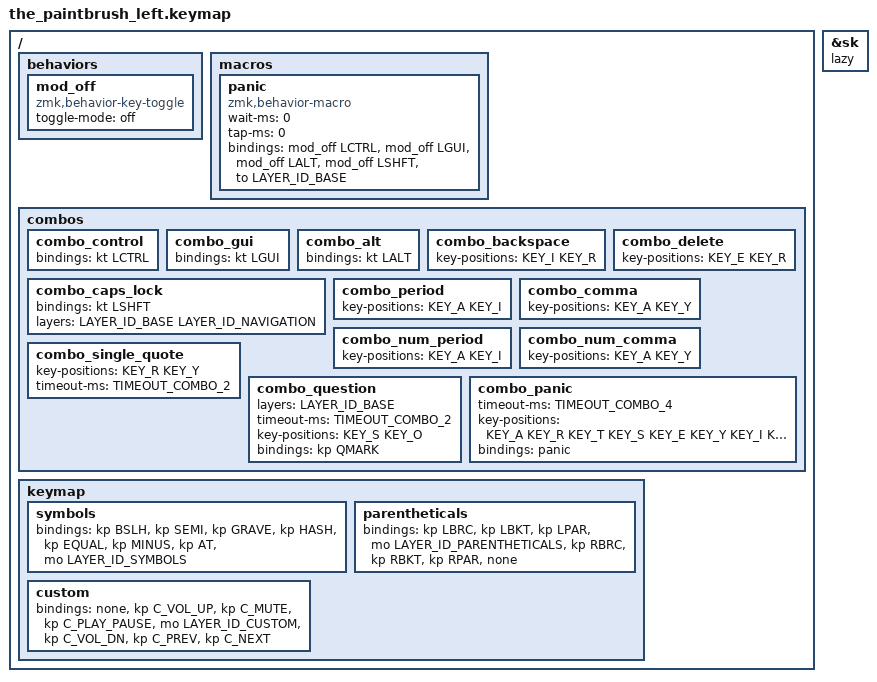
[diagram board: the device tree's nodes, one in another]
/*
 * Copyright (c) 2021 Mike "KemoNine" Crosson
 *
 * SPDX-License-Identifier: MIT
 */

#include <behaviors.dtsi>
#include <dt-bindings/zmk/keys.h>
#include <dt-bindings/zmk/bt.h>

// Left/Right
#define ARDUX_LEFT 1

// ARTS Row
#define KEY_A 3
#define KEY_R 2
#define KEY_T 1
#define KEY_S 0
// EYIO Row
#define KEY_E 7
#define KEY_Y 6
#define KEY_I 5
#define KEY_O 4

// Define Offsets
#define LEADING_NONES NONE(0,0,0)
#define MIDDLE_NONES NONE(0, 0, 0)
#define TRAILING_NONES NONE(0, 0, 0)

// Enable disconnecting for iPhone, iPad
#define ARDUX_BT_TOP &bt BT_DISC 4
#define ARDUX_BT_BOTTOM &bt BT_DISC 5

// Include main ardux.io keymap
#include "../../../ardux.dtsi"

// ARTSEY 0.9 beta overrides for this Paintbrush only. See docs/artsey-0.9.md.
// Defer one-shot Shift so it cannot interfere with the latched Shift state.
&sk { lazy; };
/ {
	behaviors {
		mod_off: mod_off {
			compatible = "zmk,behavior-key-toggle";
			#binding-cells = <1>;
			toggle-mode = "off";
		};
	};
	macros {
		panic: panic {
			compatible = "zmk,behavior-macro";
			#binding-cells = <0>;
			wait-ms = <0>;
			tap-ms = <0>;
			bindings = <&mod_off LCTRL &mod_off LGUI &mod_off LALT &mod_off LSHFT &to LAYER_ID_BASE>;
		};
	};
	combos {
		combo_control { bindings = <&kt LCTRL>; };
		combo_gui { bindings = <&kt LGUI>; };
		combo_alt { bindings = <&kt LALT>; };
		combo_backspace { key-positions = <KEY_I KEY_R>; };
		combo_delete { key-positions = <KEY_E KEY_R>; };
		/delete-node/ combo_shift_lock;
		combo_caps_lock { bindings = <&kt LSHFT>; layers = <LAYER_ID_BASE LAYER_ID_NAVIGATION>; };
		combo_period { key-positions = <KEY_A KEY_I>; };
		combo_comma { key-positions = <KEY_A KEY_Y>; };
		combo_num_period { key-positions = <KEY_A KEY_I>; };
		combo_num_comma { key-positions = <KEY_A KEY_Y>; };
		combo_single_quote { key-positions = <KEY_R KEY_Y>; timeout-ms = <TIMEOUT_COMBO_2>; };
		combo_question {
			layers = <LAYER_ID_BASE>;
			timeout-ms = <TIMEOUT_COMBO_2>;
			key-positions = <KEY_S KEY_O>;
			bindings = <&kp QMARK>;
		};
		combo_panic {
			timeout-ms = <TIMEOUT_COMBO_4>;
			key-positions = <KEY_A KEY_R KEY_T KEY_S KEY_E KEY_Y KEY_I KEY_O>;
			bindings = <&panic>;
		};
	};
	keymap {
		symbols {
			bindings = <&kp BSLH &kp SEMI &kp GRAVE &kp HASH
				&kp EQUAL &kp MINUS &kp AT &mo LAYER_ID_SYMBOLS>;
		};
		parentheticals {
			bindings = <&kp LBRC &kp LBKT &kp LPAR &mo LAYER_ID_PARENTHETICALS
				&kp RBRC &kp RBKT &kp RPAR &none>;
		};
		custom {
			bindings = <&none &kp C_VOL_UP &kp C_MUTE &kp C_PLAY_PAUSE
				&mo LAYER_ID_CUSTOM &kp C_VOL_DN &kp C_PREV &kp C_NEXT>;
		};
	};
};
